# S6E1A1xC register map
Vendor: Cypress; File version: 2.1
CPU: CM0PLUS r0p1, little endian, no MPU, no FPU, 2 interrupt priority bits
Registers are 32-bit, read-write, reset 0x0 unless marked. A register's access mark holds for its fields unless they carry their own. Offsets are from the block's base; [hi:lo] are bit positions; {n}, {i} and the like mark numbered series; 'fields as' and 'values as' point back to an identical list.

## WC — Watch Counter
Base 0x4003A000
0x00 WCRD 8-bit ro — Watch Counter Read Register [BHW]
  [5:0] CTR — Counter read bits
0x01 WCRL 8-bit — Watch Counter Reload Register [BHW]
  [5:0] RLC — Counter reload value setting bits
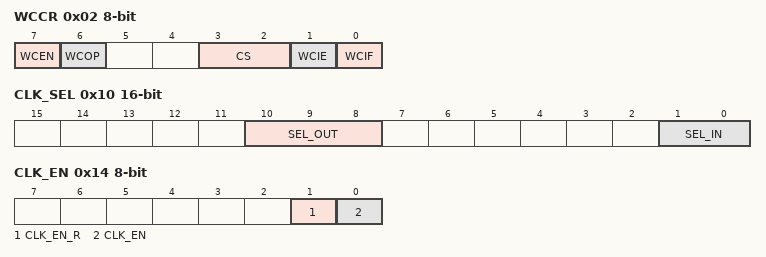
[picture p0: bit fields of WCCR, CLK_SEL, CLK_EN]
0x02 WCCR 8-bit — Watch Counter Control Register [BHW]
  [7] WCEN — Watch counter operation enable bit
  [6] WCOP ro — Watch counter operating state flag
  [3:2] CS — Count clock select bits
  [1] WCIE — Interrupt request enable bit
  [0] WCIF — Interrupt request flag bit
0x10 CLK_SEL 16-bit — Clock Selection Register [BHW]
  [10:8] SEL_OUT — Output clock selection bit
  [1:0] SEL_IN — Input clock selection bit
0x14 CLK_EN 8-bit — Division Clock Enable Register [BHW]
  [1] CLK_EN_R — Division clock enable read bit
  [0] CLK_EN — Division clock enable bit

## LSCRP — Low-speed CR Prescaler Register
Base 0x4003C000
0x00 LCR_PRSLD 8-bit — Low-speed CR Prescaler Control Register [BHW]
  [5:0] LCR_PRSLD — Low-speed CR Prescaler Load

## DMAC — DMAC Registers
Base 0x40060000
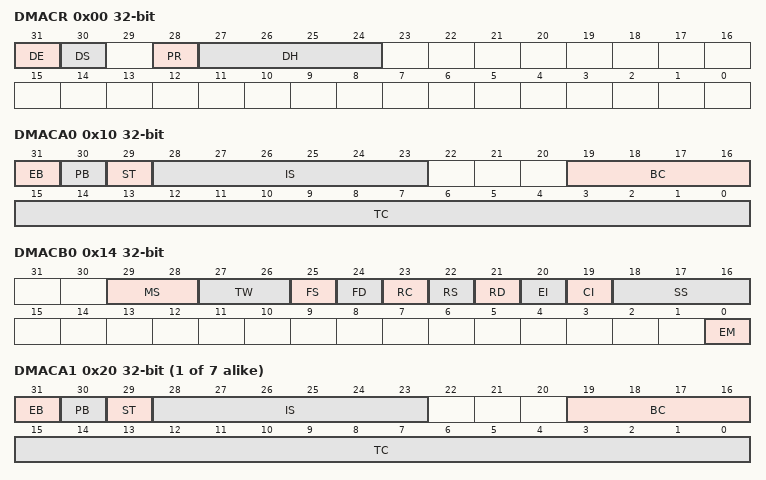
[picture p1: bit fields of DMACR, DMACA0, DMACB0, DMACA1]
0x00 DMACR — Entire DMAC Configuration Register [BHW]
  [31] DE — DMA Enable (all-channel operation enable bit)
  [30] DS — DMA Stop
  [28] PR — Priority Rotation
  [27:24] DH — DMA Halt (All-channel pause bit)
0x10 DMACA0 — Configuration A Register [BHW]
  [31] EB — Enable bit (individual-channel operation enable bit)
  [30] PB — Pause bit (individual-channel pause bit)
  [29] ST — Software Trigger
  [28:23] IS — Input Select
  [19:16] BC — Block Count
  [15:0] TC — Transfer Count
0x14 DMACB0 — Configuration B Register [BHW]
  [29:28] MS — Mode Select
  [27:26] TW — Transfer Width
  [25] FS — Fixed Source
  [24] FD — Fixed Destination
  [23] RC — Reload Count (BC/TC reload)
  [22] RS — Reload Source
  [21] RD — Reload Destination
  [20] EI — Error Interrupt (unsuccessful transfer completion interrupt enable)
  [19] CI — Completion Interrupt (successful transfer completion interrupt enable)
  [18:16] SS — Stop Status (stop status notification)
  [0] EM — Enable bit Mask (EB bit clear mask)
{0x18+0x10*i} DMACSA{i} (i=0..7) — Transfer Source Address Register {i} [BHW]
{0x1C+0x10*i} DMACDA{i} (i=0..7) — Transfer Destination Address Register {i} [BHW]
{0x10+0x10*i} DMACA{i} (i=1..7) — Configuration A Register {i} [BHW]
  fields as DMACA0
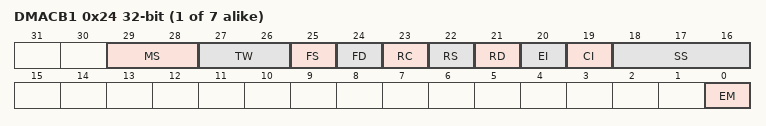
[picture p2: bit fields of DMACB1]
{0x14+0x10*i} DMACB{i} (i=1..7) — Configuration B Register {i} [BHW]
  fields as DMACB0

## MTB_DWT — Micro Trace Buffer Data Watchpoint and Trace Registers
Base 0xF0001000
0x00 CMP_ADDR_START — MTB_DWT Address Compare Start trace Register [BHW]
  [31:0] ADCMP_STA — MTB_DWT address comparison start trace bits
0x04 CMP_DATA_START — MTB_DWT Data Compare Start trace Register [BHW]
  [31:0] DTCMP_STA — MTB_DWT data comparison start trace bits
0x08 CMP_MASK_START — MTB_DWT Mask Data Compare Start Trace Register [BHW]
  [31:0] MSK_STA — MTB_DWT data compare start trace register mask bits
0x10 CMP_ADDR_STOP — MTB_DWT Address Compare Stop trace Register [BHW]
  [31:0] ADCMP_STO — MTB_DWT address comparison stop trace bits
0x14 CMP_DATA_STOP — MTB_DWT Data Compare Stop trace Register [BHW]
  [31:0] DTCMP_STO — MTB_DWT data comparison stop trace bits
0x18 CMP_MASK_STOP — MTB_DWT Mask Data Compare Stop Trace Register [BHW]
  [31:0] MSK_STO — MTB_DWT data compare stop trace register mask bits
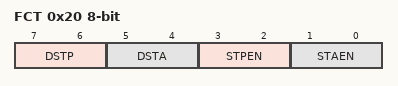
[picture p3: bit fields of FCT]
0x20 FCT 8-bit — MTB_DWT Function Register [BHW]
  [7:6] DSTP — Data size stop bits
  [5:4] DSTA — Data size start bits
  [3:2] STPEN — Enable MTB_DWT stop MTB function bits
  [1:0] STAEN — Enable MTB_DWT start MTB function bits
{0xFC0+4i} PID{i} ro (i=4..7) — Peripheral ID{i} Register [BHW]
  [31:0] PERID — Peripheral ID bits
0xFE0 PID0 ro reset 0x16 — Peripheral ID0 Register [BHW]
  [31:0] PERID — Peripheral ID bits
0xFE4 PID1 ro reset 0x48 — Peripheral ID1 Register [BHW]
  [31:0] PERID — Peripheral ID bits
0xFE8 PID2 ro reset 0x8 — Peripheral ID2 Register [BHW]
  [31:0] PERID — Peripheral ID bits
0xFEC PID3 ro — Peripheral ID3 Register [BHW]
  [31:0] PERID — Peripheral ID bits
0xFF0 CID0 ro reset 0xD — Component ID0 Register [BHW]
  [31:0] CPNTID — Component ID bits
0xFF4 CID1 ro reset 0x90 — Component ID1 Register [BHW]
  [31:0] CPNTID — Component ID bits
0xFF8 CID2 ro reset 0x5 — Component ID2 Register [BHW]
  [31:0] CPNTID — Component ID bits
0xFFC CID3 ro reset 0xB1 — Component ID3 Register [BHW]
  [31:0] CPNTID — Component ID bits
